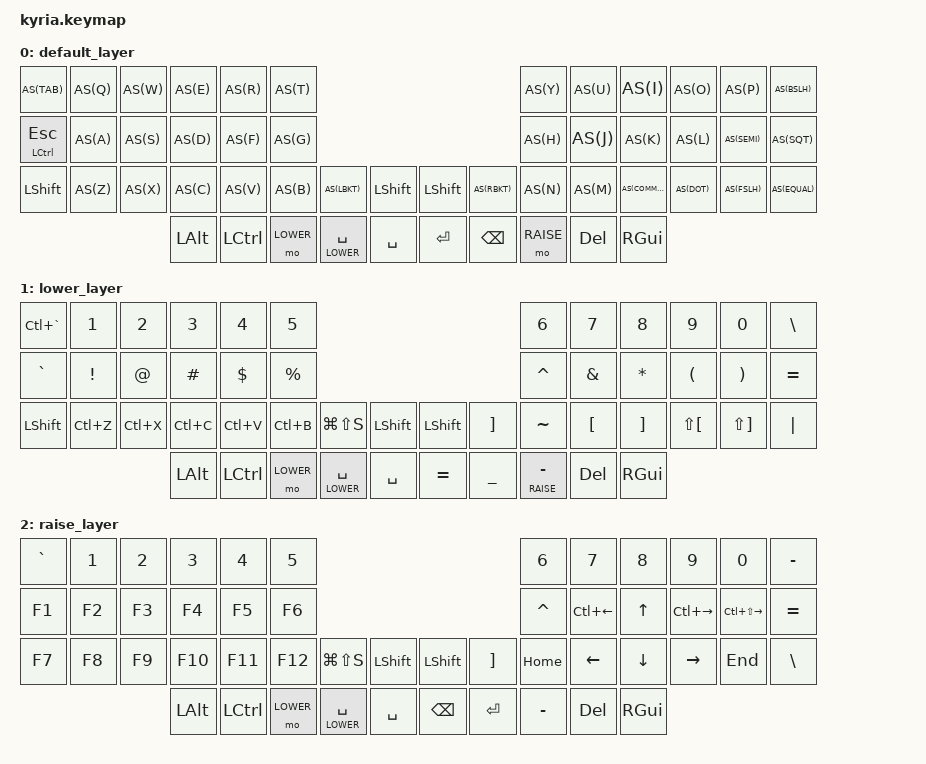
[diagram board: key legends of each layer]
/*
 * Copyright (c) 2020 The ZMK Contributors
 *
 * SPDX-License-Identifier: MIT
 */


#include <behaviors.dtsi>
#include <dt-bindings/zmk/keys.h>
#include <dt-bindings/zmk/bt.h>
#include <dt-bindings/zmk/ext_power.h>
#include <dt-bindings/zmk/rgb.h>


#define DEFAULT 0
#define LOWER   1
#define RAISE   2
#define AS(keycode) &as LS(keycode) keycode

/ {
	behaviors {
        as: auto_shift {
		compatible = "zmk,behavior-hold-tap";
		label = "AUTO_SHIFT";
		#binding-cells = <2>;
		tapping_term_ms = <135>;
		quick_tap_ms = <0>;
		flavor = "tap-preferred";
		bindings = <&kp>, <&kp>;
            };
        };

	keymap {
		compatible = "zmk,keymap";

		default_layer {
// ---------------------------------------------------------------------------------------------------------------------------------
// |  TAB         |  Q  |  W  |  E   |  R   |  T   |                                              |  Y    |  U    |  I    |  O    |   P   |   \   |
// | ESC/CTRL     |  A  |  S  |  D   |  F   |  G   |                                              |  H    |  J    |  K    |  L    |   ;   |   '   |
// | SHIFT        |  Z  |  X  |  C   |  V   |  B   | LBKT     | L SHIFT  |  | L SHIFT  |  RBKT    |  N    |  M    |  ,    |  .    |   /   | EQUAL |
//                            | LALT | LCTRL| RET  |  SPACE   |   SPACE  |  |  RET     |   BSPC   | TAB   | BSPC  | R-ALT |
			bindings =  < 
	AS(TAB)     	AS(Q) 	AS(W) 		AS(E) 		AS(R) 		AS(T)          		                             					AS(Y)    	AS(U)  	AS(I)    	AS(O)  	 AS(P)   	AS(BSLH)
	&mt LCTRL ESC 	AS(A) 	AS(S) 		AS(D) 		AS(F) 		AS(G)          		                             					AS(H)    	AS(J)  	AS(K)    	AS(L)  	 AS(SEMI)	AS(SQT)
	&kp LSHFT     	AS(Z) 	AS(X) 		AS(C) 		AS(V) 		AS(B)   	AS(LBKT)  		&kp LSHFT      &kp LSHFT	AS(RBKT)   	AS(N)    	AS(M)  	AS(COMMA)	AS(DOT)	 AS(FSLH)	AS(EQUAL)
	                    				&kp LALT 	&kp LCTRL 	&mo LOWER   &lt LOWER SPACE &kp SPACE      &kp RET  	&kp BSPC    &mo RAISE 	&kp DEL &kp RGUI
			>;
		};

		lower_layer {
			bindings =  < 
	&kp LC(GRAVE)  	&kp N1 		&kp N2		&kp N3 		&kp N4 		&kp N5                                                 				&kp N6			&kp N7    		&kp N8			&kp N9  		&kp N0    		&kp BSLH
	&kp GRAVE 		&kp EXCL 	&kp AT 		&kp HASH 	&kp DOLLAR 	&kp PERCENT                                            				&kp CARET 		&kp AMPS  		&kp ASTRK 		&kp LPAR  		&kp RPAR 		&kp EQUAL
	&kp LSHFT     	&kp LC(Z) 	&kp LC(X)   &kp LC(C) 	&kp LC(V) 	&kp LC(B)   &kp LG(LS(S)) 	&kp LSHFT 		&kp LSHFT	&kp RBKT	&kp TILDE  		&kp LBKT   		&kp RBKT 		&kp LS(LBKT)	&kp LS(RBKT) 	&kp PIPE
	                    					&kp LALT 	&kp LCTRL 	&mo LOWER  	&lt LOWER SPACE	&kp SPACE      	&kp EQUAL  	&kp UNDER	&lt RAISE MINUS &kp DEL  		&kp RGUI
			>;
		};

		raise_layer {
			bindings =  < 
	&kp GRAVE     	&kp N1 		&kp N2		&kp N3 		&kp N4 		&kp N5                                                   	    	&kp N6			&kp N7    		&kp N8			&kp N9  		&kp N0    			&kp MINUS
	&kp F1	 		&kp F2 		&kp F3 		&kp F4 		&kp F5 		&kp F6                                                     			&kp CARET 		&kp LC(LEFT)  	&kp UP 			&kp LC(RIGHT)  	&kp LC(LS(RIGHT)) 	&kp EQUAL
	&kp F7     		&kp F8 		&kp F9  	&kp F10 	&kp F11 	&kp F12   	&kp LG(LS(S)) 	&kp LSHFT   	&kp LSHFT	&kp RBKT	&kp HOME    	&kp LEFT    	&kp DOWN 		&kp RIGHT		&kp END 			&kp BSLH
	                    					&kp LALT 	&kp LCTRL 	&mo LOWER  	&lt LOWER SPACE &kp SPACE      	&kp BSPC  	&kp RET		&kp MINUS 		&kp DEL  		&kp RGUI
			>;
		};



	};
};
